# RN831X_RN861X_MCU register map
File version: v0.0.1
CPU: RN831X_RN861X_MCU r1p0, little endian, MPU, no FPU
Registers are 32-bit, read-write, reset 0x0 unless marked. A register's access mark holds for its fields unless they carry their own. Offsets are from the block's base; [hi:lo] are bit positions; 'fields as' and 'values as' point back to an identical list.

## TC0_CORE0 — A 32-bit timer
Base 0x2009C000
Same registers: TC1_CORE0 0x200A0000, TC0_CORE1 0xA009C000, TC1_CORE1 0xA00A0000
0x00 CNT ro — current counting value register
  [31:0] CNT — current Timer counter value bits
0x04 PS access not given — prescaler value register of the counter clock
  [15:0] PS — prescaler value bits of the counter clock
0x0C DN access not given — target counting value register
  [31:0] DN — target counting value bits
0x14 CCD0 access not given — capture(compare) channel No.0 data register
  [31:0] CCD0 — capture(compare) channel No.0 data bits
0x18 CCD1 access not given — capture(compare) channel No.1 data register
  [31:0] CCD1 — capture(compare) channel No.1 data bits
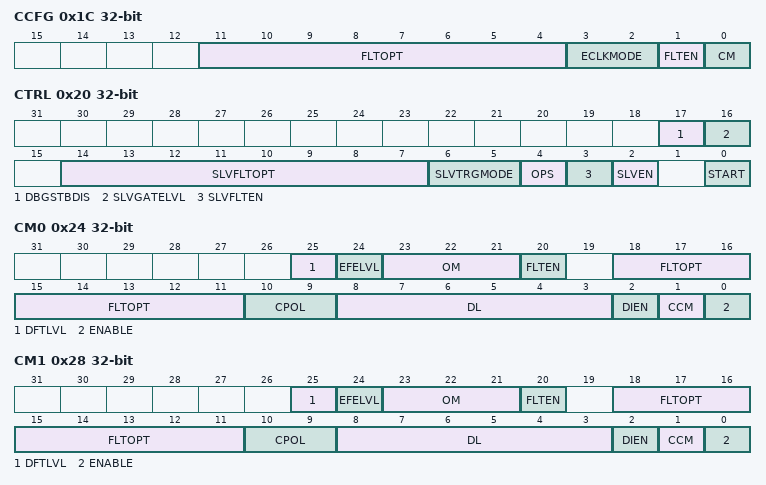
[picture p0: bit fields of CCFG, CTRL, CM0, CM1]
0x1C CCFG — clock config register
  [11:4] FLTOPT — external clock source filter clock cycles set bits
  [3:2] ECLKMODE — external clock mode selection bits
    0=PE (every posedge found on input recognized as a couting event); 1=NE (every negedge found on input recognized as a couting event); 2=BE (both posedge and negedge found on input recognized as a as a couting event)
  [1] FLTEN — external clock source filter enable bit
  [0] CM — clock mode selection bit
    0=INT (using on-chip system clock as input counting clock); 1=EXT (using external clock(to the timer) as input counting clock(refer to bitfield CS of register TC_CCFG for clock selection))
0x20 CTRL — control register
  [17] DBGSTBDIS — debugger halt standby enable/disable bit
    0=PAUSE (halt counting when SoC halted by debugger); 1=COUNTINUE (keep counting when SoC halted by debugger)
  [16] SLVGATELVL — slave mode gating level control bit
    0=LOW (select low level sensitive gate); 1=HIGH (select high level sensitive gate)
  [14:7] SLVFLTOPT — slave mode input filter parameter configuration bits
  [6:5] SLVTRGMODE — slave mode polarity control selection bits
    0=PE (clean internal counter at posedge); 1=NE (clean internal counter at negedge); 2=BE (clean internal counter at both posedge and negedge); 3=GM (level sensitive gate control)
  [4] OPS — one pulse mode selection bit
    0=DIS (one pulse mode disabled(timer continue counting when overflow)); 1=EN (one pulse mode enabled(timer stop counting when overflow))
  [3] SLVFLTEN — slave mode input filter enable
  [2] SLVEN — slave mode enable
  [0] START — timer start bit
0x24 CM0 access not given — capture(compare) channel No.0 mode register
  [25] DFTLVL — compare valid default level set bit
  [24] EFELVL — compare valid output level set bit
  [23:21] OM — compare output mode cfg bits
    0=NUL (no output generated); 1=VL (set as valid level); 2=INVL (set as invalid level); 3=TOG (toggle output); 4=FVL (force as valid level); 5=FINVL (force as invalid level); 6=PWM1 (when tc_cnt less than tc_ccdx, set output as valid level); 7=PWM2 (when tc_cnt greater than tc_ccdx, set output as valid level)
  [20] FLTEN — capture filter enable bit
  [18:11] FLTOPT — capture filter parameter set bits
  [10:9] CPOL — capture polarity selection bits
    0=PE (capture on posedge); 1=NE (capture on negedge); 2=BE (capture on both posedge and negedge)
  [8:3] DL — compare dead zone length configuration bits (only for PWM1/PWM2)
  [2] DIEN — compare dead zone insertion enable bit (only for PWM1/PWM2)
  [1] CCM — capture(compare) selection bit
    0=IC (select as input capture); 1=OC (select as output compare)
  [0] ENABLE — channel enable bit
0x28 CM1 access not given — capture(compare) channel No.1 mode register
  fields as CM0
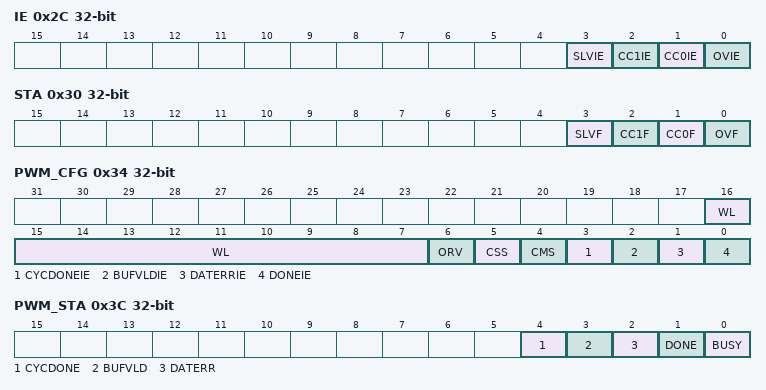
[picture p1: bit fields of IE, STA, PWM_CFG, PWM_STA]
0x2C IE access not given — Interrupt enable register
  [3] SLVIE — slave interrupt enable
  [2] CC1IE — compare(caputure) channel No.1 interrupt enable
  [1] CC0IE — compare(caputure) channel No.0 interrupt enable
  [0] OVIE — overflow interrupt enable
0x30 STA access not given — status register
  [3] SLVF write-1-clears — slave event flag
  [2] CC1F write-1-clears — compare(capture) channel No.1 flag
  [1] CC0F write-1-clears — compare(capture) channel No.0 flag
  [0] OVF write-1-clears — overflow interrupt flag
0x34 PWM_CFG access not given — PWM config register
  [16:7] WL — PWM wave length config bits (available when ORV=0)
  [6] ORV — PWM output remain period mode selection bit
    0=WLC (wave length configurable); 1=ORV (output remain valid)
  [5] CSS — PWM complete signal selection bit
    0=CS (select to finish output last complete signal while module disabled); 1=BS (select to break output signal while module disabled)
  [4] CMS — PWM control mode selection bit
    0=DMA (select as DMA mode); 1=SOFT (select as soft control mode)
  [3] CYCDONEIE — output cycle done interrupt enable bit
    0=DIS (disable); 1=EN (enable)
  [2] BUFVLDIE — PWM buffer empty interrupt enable bit (only soft mode available)
    0=DIS (disable); 1=EN (enable)
  [1] DATERRIE — data error interrupt enable bit
    0=DIS (disable); 1=EN (enable)
  [0] DONEIE — PWM output done interrupt enable bit
    0=DIS (disable); 1=EN (enable)
0x38 PWM_CTRL access not given — PWM control register
  [0] EN — PWM enable bit
0x3C PWM_STA access not given — PWM status register
  [4] CYCDONE write-1-clears — PWM output cycle done interrupt flag
  [3] BUFVLD write-1-clears — PWM buffer empty interrupt flag
  [2] DATERR write-1-clears — PWM data error interrupt flag
  [1] DONE write-1-clears — PWM output done interrupt flag
  [0] BUSY — PWM output busy flag
0x40 PWM_CNT access not given — PWM current counting value register
  [15:0] N_PWM — PWM cycle Timer counter value bits
0x44 PWM_DMA_BADR — PWM DMA base address register
  [15:0] BADR — DMA begin addr configuration bits
0x48 PWM_DMA_LEN — PWM DMA length register
  [15:0] LEN — DMA length configuration bits
0x4C PWM_DMA_ADR ro — PWM DMA current address register
  [15:0] ADR — current DMA addr bits
